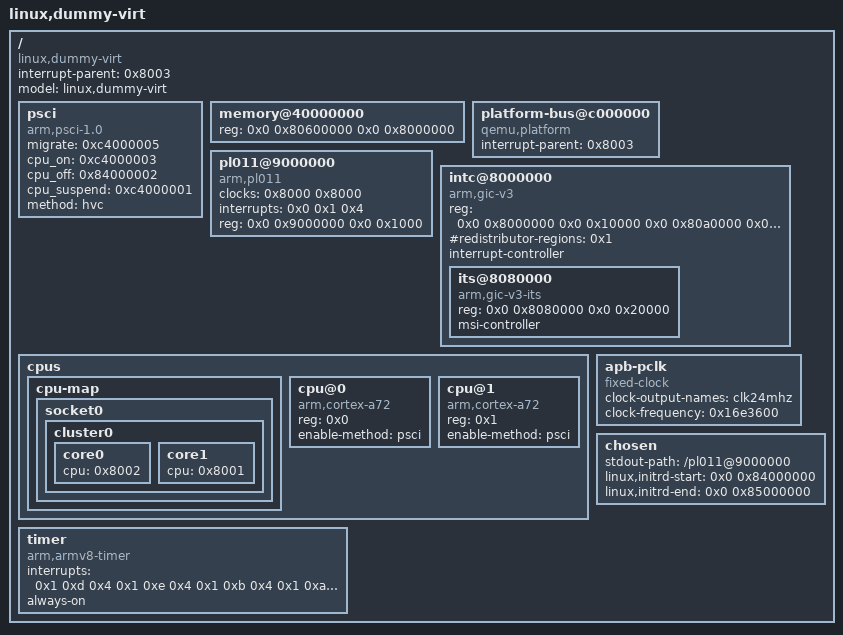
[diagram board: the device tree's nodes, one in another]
/dts-v1/;

/ {
	interrupt-parent = <0x8003>;
	model = "linux,dummy-virt";
	#size-cells = <0x2>;
	#address-cells = <0x2>;
	compatible = "linux,dummy-virt";

	psci {
		migrate = <0xc4000005>;
		cpu_on = <0xc4000003>;
		cpu_off = <0x84000002>;
		cpu_suspend = <0xc4000001>;
		method = "hvc";
		compatible = "arm,psci-1.0", "arm,psci-0.2", "arm,psci";
	};

	memory@40000000 {
		reg = <0x0 0x80600000 0x0 0x8000000>;
		device_type = "memory";
	};

	platform-bus@c000000 {
		interrupt-parent = <0x8003>;
		ranges = <0x0 0x0 0xc000000 0x2000000>;
		#address-cells = <0x1>;
		#size-cells = <0x1>;
		compatible = "qemu,platform", "simple-bus";
	};

	pl011@9000000 {
		clock-names = "uartclk", "apb_pclk";
		clocks = <0x8000 0x8000>;
		interrupts = <0x0 0x1 0x4>;
		reg = <0x0 0x9000000 0x0 0x1000>;
		compatible = "arm,pl011", "arm,primecell";
	};

	intc@8000000 {
		phandle = <0x8003>;
		reg = <0x0 0x8000000 0x0 0x10000 0x0 0x80a0000 0x0 0xf60000>;
		#redistributor-regions = <0x1>;
		compatible = "arm,gic-v3";
		ranges;
		#size-cells = <0x2>;
		#address-cells = <0x2>;
		interrupt-controller;
		#interrupt-cells = <0x3>;

		its@8080000 {
			phandle = <0x8004>;
			reg = <0x0 0x8080000 0x0 0x20000>;
			#msi-cells = <0x1>;
			msi-controller;
			compatible = "arm,gic-v3-its";
		};
	};

	cpus {
		#size-cells = <0x0>;
		#address-cells = <0x1>;

		cpu-map {

			socket0 {

				cluster0 {

					core0 {
						cpu = <0x8002>;
					};

					core1 {
						cpu = <0x8001>;
					};
				};
			};
		};

		cpu@0 {
			phandle = <0x8002>;
			reg = <0x0>;
			enable-method = "psci";
			compatible = "arm,cortex-a72";
			device_type = "cpu";
		};

		cpu@1 {
			phandle = <0x8001>;
			reg = <0x1>;
			enable-method = "psci";
			compatible = "arm,cortex-a72";
			device_type = "cpu";
		};
	};

	timer {
		interrupts = <0x1 0xd 0x4 0x1 0xe 0x4 0x1 0xb 0x4 0x1 0xa 0x4>;
		always-on;
		compatible = "arm,armv8-timer", "arm,armv7-timer";
	};

	apb-pclk {
		phandle = <0x8000>;
		clock-output-names = "clk24mhz";
		clock-frequency = <0x16e3600>;
		#clock-cells = <0x0>;
		compatible = "fixed-clock";
	};

	chosen {
		stdout-path = "/pl011@9000000";
        linux,initrd-start = <0x0 0x84000000>;
        linux,initrd-end = <0x0 0x85000000>;
    };
};
